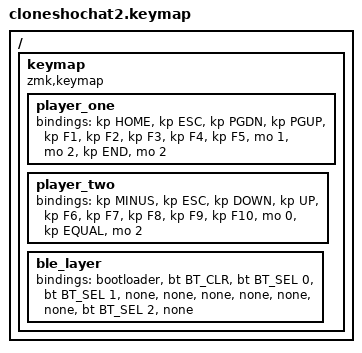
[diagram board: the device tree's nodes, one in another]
#include <behaviors.dtsi>
#include <dt-bindings/zmk/keys.h>
#include <dt-bindings/zmk/bt.h>

/{
    keymap {
        compatible = "zmk,keymap";

        player_one {
            bindings = <
                &kp HOME   
                &kp ESC    
                &kp PGDN   
                &kp PGUP   
                &kp F1     
                &kp F2     
                &kp F3     
                &kp F4     
                &kp F5     
                &mo 1 
                &mo 2      
                &kp END    
                &mo 2      
            >;
        };

        player_two {
            bindings = <
                &kp MINUS  
                &kp ESC    
                &kp DOWN   
                &kp UP     
                &kp F6     
                &kp F7     
                &kp F8     
                &kp F9     
                &kp F10    
                &mo 0      
                &kp EQUAL  
                &mo 2      
            >;
        };

        ble_layer {
            bindings = <
                &bootloader
                &bt BT_CLR
                &bt BT_SEL 0
                &bt BT_SEL 1
                &none
                &none
                &none
                &none
                &none
                &none
                &bt BT_SEL 2
                &none
            >;
        };
    };
};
